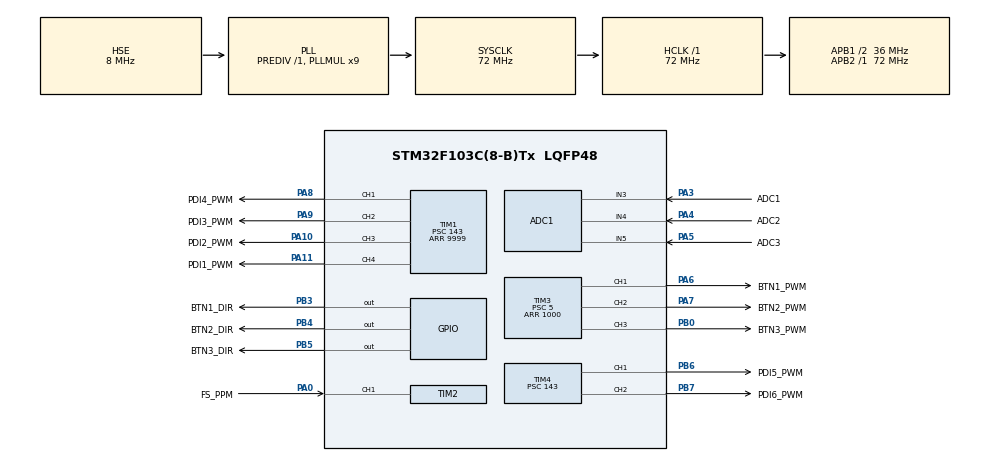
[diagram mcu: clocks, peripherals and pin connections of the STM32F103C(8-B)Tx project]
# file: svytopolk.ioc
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ADC1.Channel-0\#ChannelRegularConversion=ADC_CHANNEL_3
ADC1.NbrOfConversionFlag=1
ADC1.Rank-0\#ChannelRegularConversion=1
ADC1.SamplingTime-0\#ChannelRegularConversion=ADC_SAMPLETIME_1CYCLE_5
ADC1.master=1
Mcu.Family=STM32F1
Mcu.Name=STM32F103C(8-B)Tx
Mcu.Package=LQFP48
NVIC.PriorityGroup=NVIC_PRIORITYGROUP_4
NVIC.TIM1_BRK_IRQn=true\:0\:0\:false\:false\:true\:true\:true\:true
NVIC.TIM1_CC_IRQn=true\:0\:0\:false\:false\:true\:true\:true\:true
NVIC.TIM1_TRG_COM_IRQn=true\:0\:0\:false\:false\:true\:true\:true\:true
NVIC.TIM1_UP_IRQn=true\:0\:0\:false\:false\:true\:true\:true\:true
NVIC.TIM2_IRQn=true\:0\:0\:false\:false\:true\:true\:true\:true
NVIC.TIM3_IRQn=true\:0\:0\:false\:false\:true\:true\:true\:true
PA0-WKUP.GPIO_Label=FS_PPM
PA0-WKUP.Signal=S_TIM2_CH1_ETR
PA10.GPIO_Label=PDI2_PWM
PA10.Signal=S_TIM1_CH3
PA11.GPIO_Label=PDI1_PWM
PA11.Signal=S_TIM1_CH4
PA13.Mode=Serial_Wire
PA13.Signal=SYS_JTMS-SWDIO
PA14.Mode=Serial_Wire
PA14.Signal=SYS_JTCK-SWCLK
PA3.GPIO_Label=ADC1
PA3.Signal=ADCx_IN3
PA4.GPIO_Label=ADC2
PA4.Signal=ADCx_IN4
PA5.GPIO_Label=ADC3
PA5.Signal=ADCx_IN5
PA6.GPIO_Label=BTN1_PWM
PA6.Signal=S_TIM3_CH1
PA7.GPIO_Label=BTN2_PWM
PA7.Signal=S_TIM3_CH2
PA8.GPIO_Label=PDI4_PWM
PA8.Signal=S_TIM1_CH1
PA9.GPIO_Label=PDI3_PWM
PA9.Signal=S_TIM1_CH2
PB0.GPIO_Label=BTN3_PWM
PB0.Signal=S_TIM3_CH3
PB3.GPIO_Label=BTN1_DIR
PB3.Signal=GPIO_Output
PB4.GPIO_Label=BTN2_DIR
PB4.Signal=GPIO_Output
PB5.GPIO_Label=BTN3_DIR
PB5.Signal=GPIO_Output
PB6.GPIO_Label=PDI5_PWM
PB6.Signal=S_TIM4_CH1
PB7.GPIO_Label=PDI6_PWM
PB7.Signal=S_TIM4_CH2
PD0-OSC_IN.Mode=HSE-External-Oscillator
PD0-OSC_IN.Signal=RCC_OSC_IN
PD1-OSC_OUT.Mode=HSE-External-Oscillator
PD1-OSC_OUT.Signal=RCC_OSC_OUT
ProjectManager.HeapSize=0x200
ProjectManager.StackSize=0x400
ProjectManager.TargetToolchain=STM32CubeIDE
RCC.ADCPresc=RCC_ADCPCLK2_DIV6
RCC.AHBFreq_Value=72000000
RCC.APB1CLKDivider=RCC_HCLK_DIV2
RCC.APB1Freq_Value=36000000
RCC.APB1TimFreq_Value=72000000
RCC.APB2Freq_Value=72000000
RCC.APB2TimFreq_Value=72000000
RCC.HCLKFreq_Value=72000000
RCC.PLLMUL=RCC_PLL_MUL9
RCC.PLLSourceVirtual=RCC_PLLSOURCE_HSE
RCC.SYSCLKFreq_VALUE=72000000
RCC.SYSCLKSource=RCC_SYSCLKSOURCE_PLLCLK
RCC.USBFreq_Value=72000000
SH.ADCx_IN3.0=ADC1_IN3,IN3
SH.ADCx_IN4.0=ADC1_IN4,IN4
SH.ADCx_IN5.0=ADC1_IN5,IN5
SH.S_TIM1_CH1.0=TIM1_CH1,PWM Generation1 CH1
SH.S_TIM1_CH2.0=TIM1_CH2,PWM Generation2 CH2
SH.S_TIM1_CH3.0=TIM1_CH3,PWM Generation3 CH3
SH.S_TIM1_CH4.0=TIM1_CH4,PWM Generation4 CH4
SH.S_TIM2_CH1_ETR.0=TIM2_CH1,TriggerSource_TI1FP1
SH.S_TIM2_CH1_ETR.1=TIM2_CH1,Input_Capture1_from_TI1
SH.S_TIM3_CH1.0=TIM3_CH1,PWM Generation1 CH1
SH.S_TIM3_CH2.0=TIM3_CH2,PWM Generation2 CH2
SH.S_TIM3_CH3.0=TIM3_CH3,PWM Generation3 CH3
SH.S_TIM4_CH1.0=TIM4_CH1,PWM Generation1 CH1
SH.S_TIM4_CH2.0=TIM4_CH2,PWM Generation2 CH2
TIM1.Channel-PWM\ Generation1\ CH1=TIM_CHANNEL_1
TIM1.Channel-PWM\ Generation2\ CH2=TIM_CHANNEL_2
TIM1.Channel-PWM\ Generation3\ CH3=TIM_CHANNEL_3
TIM1.Channel-PWM\ Generation4\ CH4=TIM_CHANNEL_4
TIM1.Period=9999
TIM1.Prescaler=143
TIM2.Channel-Input_Capture1_from_TI1=TIM_CHANNEL_1
TIM2.ICPolarity_CH1=TIM_INPUTCHANNELPOLARITY_RISING
TIM2.Prescaler=71
TIM3.Channel-PWM\ Generation1\ CH1=TIM_CHANNEL_1
TIM3.Channel-PWM\ Generation2\ CH2=TIM_CHANNEL_2
TIM3.Channel-PWM\ Generation3\ CH3=TIM_CHANNEL_3
TIM3.Period=1000
TIM3.Prescaler=5
TIM4.Channel-PWM\ Generation1\ CH1=TIM_CHANNEL_1
TIM4.Channel-PWM\ Generation2\ CH2=TIM_CHANNEL_2
TIM4.Period=9999
TIM4.Prescaler=143
VP_TIM1_VS_ClockSourceINT.Mode=Internal
VP_TIM2_VS_ClockSourceINT.Mode=Internal
VP_TIM2_VS_ControllerModeReset.Mode=Reset Mode
VP_TIM4_VS_ClockSourceINT.Mode=Internal
board=custom

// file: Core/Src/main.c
/* USER CODE BEGIN Header */
/**
  ******************************************************************************
  * @file           : main.c
  * @brief          : Main program body
  ******************************************************************************
  * @attention
  *
  * Copyright (c) 2023 STMicroelectronics.
  * All rights reserved.
  *
  * This software is licensed under terms that can be found in the LICENSE file
  * in the root directory of this software component.
  * If no LICENSE file comes with this software, it is provided AS-IS.
  *
  ******************************************************************************
  */
/* USER CODE END Header */
#include "main.h"
#include "adc.h"
#include "tim.h"
#include "gpio.h"

/* USER CODE BEGIN Includes */
#include "drive.h"
#include "control.h"

/* USER CODE END Includes */

void SystemClock_Config(void);

int main(void)
{

  /* MCU Configuration--------------------------------------------------------*/

  /* Reset of all peripherals, Initializes the Flash interface and the Systick. */
  HAL_Init();

  /* Configure the system clock */
  SystemClock_Config();

  /* Initialize all configured peripherals */
  MX_GPIO_Init();
  MX_ADC1_Init();
  MX_TIM1_Init();
  MX_TIM2_Init();
  MX_TIM3_Init();
  MX_TIM4_Init();
  /* USER CODE BEGIN 2 */

  //Включение приемника
  HAL_TIM_IC_Start_IT(&htim2, TIM_CHANNEL_1);

  //Приведение в стартовую позицию
//  HAL_TIM_PWM_Start(&htim1, TIM_CHANNEL_1);

//  start_pos(3);

  robot.demo.constructor = &constrction_program;
  robot.demo.destructor = &destrction_program;

  robot_init();
  robot.demo.constructor();
  /* USER CODE END 2 */

  /* Infinite loop */
  /* USER CODE BEGIN WHILE */
  while (1)
  {
	  if(robot.isChanged)
	  {
		  robot.demo.destructor();
		  robot.demo.constructor();
	  }
	  else
		  robot.demo.runner();

    /* USER CODE END WHILE */

  }
}

void SystemClock_Config(void)
{
  RCC_OscInitTypeDef RCC_OscInitStruct = {0};
  RCC_ClkInitTypeDef RCC_ClkInitStruct = {0};
  RCC_PeriphCLKInitTypeDef PeriphClkInit = {0};

  /** Initializes the RCC Oscillators according to the specified parameters
  * in the RCC_OscInitTypeDef structure.
  */
  RCC_OscInitStruct.OscillatorType = RCC_OSCILLATORTYPE_HSE;
  RCC_OscInitStruct.HSEState = RCC_HSE_ON;
  RCC_OscInitStruct.HSEPredivValue = RCC_HSE_PREDIV_DIV1;
  RCC_OscInitStruct.HSIState = RCC_HSI_ON;
  RCC_OscInitStruct.PLL.PLLState = RCC_PLL_ON;
  RCC_OscInitStruct.PLL.PLLSource = RCC_PLLSOURCE_HSE;
  RCC_OscInitStruct.PLL.PLLMUL = RCC_PLL_MUL9;
  if (HAL_RCC_OscConfig(&RCC_OscInitStruct) != HAL_OK)
  {
    Error_Handler();
  }

  /** Initializes the CPU, AHB and APB buses clocks
  */
  RCC_ClkInitStruct.ClockType = RCC_CLOCKTYPE_HCLK|RCC_CLOCKTYPE_SYSCLK
                              |RCC_CLOCKTYPE_PCLK1|RCC_CLOCKTYPE_PCLK2;
  RCC_ClkInitStruct.SYSCLKSource = RCC_SYSCLKSOURCE_PLLCLK;
  RCC_ClkInitStruct.AHBCLKDivider = RCC_SYSCLK_DIV1;
  RCC_ClkInitStruct.APB1CLKDivider = RCC_HCLK_DIV2;
  RCC_ClkInitStruct.APB2CLKDivider = RCC_HCLK_DIV1;

  if (HAL_RCC_ClockConfig(&RCC_ClkInitStruct, FLASH_LATENCY_2) != HAL_OK)
  {
    Error_Handler();
  }
  PeriphClkInit.PeriphClockSelection = RCC_PERIPHCLK_ADC;
  PeriphClkInit.AdcClockSelection = RCC_ADCPCLK2_DIV6;
  if (HAL_RCCEx_PeriphCLKConfig(&PeriphClkInit) != HAL_OK)
  {
    Error_Handler();
  }
}

void Error_Handler(void)
{
  __disable_irq();
  while (1)
  {
  }
}
